# AT90CAN64 device description
Architecture: AVR8; Family: megaAVR
Registers are 8-bit, access not given, no defined reset value unless marked. A register's access mark holds for its fields unless they carry their own. Offsets are from the block's base; [hi:lo] are bit positions; 'fields as' and 'values as' point back to an identical list.

## USART1 — USART
Instances: USART1 0x00
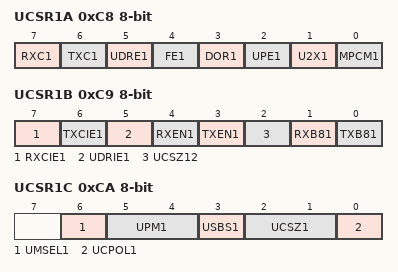
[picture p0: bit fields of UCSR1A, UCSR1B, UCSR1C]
0xC8 UCSR1A — USART Control and Status Register A
  [7] RXC1 — USART Receive Complete
  [6] TXC1 — USART Transmitt Complete
  [5] UDRE1 — USART Data Register Empty
  [4] FE1 — Framing Error
  [3] DOR1 — Data overRun
  [2] UPE1 — Parity Error
  [1] U2X1 — Double the USART transmission speed
  [0] MPCM1 — Multi-processor Communication Mode
0xC9 UCSR1B — USART Control and Status Register B
  [7] RXCIE1 — RX Complete Interrupt Enable
  [6] TXCIE1 — TX Complete Interrupt Enable
  [5] UDRIE1 — USART Data register Empty Interrupt Enable
  [4] RXEN1 — Receiver Enable
  [3] TXEN1 — Transmitter Enable
  [2] UCSZ12 — Character Size
  [1] RXB81 — Receive Data Bit 8
  [0] TXB81 — Transmit Data Bit 8
0xCA UCSR1C — USART Control and Status Register C
  [6] UMSEL1 — USART Mode Select
    0=Asynchronous Operation; 1=Synchronous Operation
  [5:4] UPM1 — Parity Mode Bits
    0=Disabled; 2=Enabled, Even Parity; 3=Enabled, Odd Parity
  [3] USBS1 — Stop Bit Select
    0=1-bit; 1=2-bit
  [2:1] UCSZ1 — Character Size
  [0] UCPOL1 — Clock Polarity
0xCC UBRR1 16-bit bits used 11:0 — USART Baud Rate Register t Bytes
0xCE UDR1 — USART I/O Data Register

## CPU — CPU Registers
Instances: CPU 0x00
Parameters: CORE_VERSION=V2E
0x3E GPIOR0 — General Purpose IO Register 0
0x4A GPIOR1 — General Purpose IO Register 1
0x4B GPIOR2 — General Purpose IO Register 2
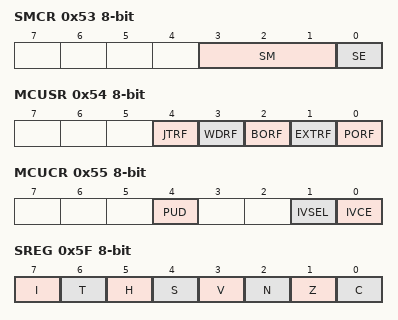
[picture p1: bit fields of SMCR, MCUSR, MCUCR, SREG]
0x53 SMCR — Sleep Mode Control Register
  [3:1] SM — Sleep Mode Select bits
    0=IDLE; 1=ADC (ADC Noise Reduction (If Available)); 2=PDOWN (Power Down); 3=PSAVE (Power Save); 6=STDBY (Standby)
  [0] SE — Sleep Enable
0x54 MCUSR — MCU Status Register
  [4] JTRF — JTAG Reset Flag
  [3] WDRF — Watchdog Reset Flag
  [2] BORF — Brown-out Reset Flag
  [1] EXTRF — External Reset Flag
  [0] PORF — Power-on reset flag
0x55 MCUCR — MCU Control Register
  [4] PUD — Pull-up disable
  [1] IVSEL — Interrupt Vector Select
  [0] IVCE — Interrupt Vector Change Enable
0x5B RAMPZ — RAM Page Z Select Register - Not used.
  [0] RAMPZ0 — RAM Page Z Select Register Bit 0
0x5D SP 16-bit — Stack Pointer
0x5F SREG — Status Register
  [7] I — Global Interrupt Enable
  [6] T — Bit Copy Storage
  [5] H — Half Carry Flag
  [4] S — Sign Bit
  [3] V — Two's Complement Overflow Flag
  [2] N — Negative Flag
  [1] Z — Zero Flag
  [0] C — Carry Flag
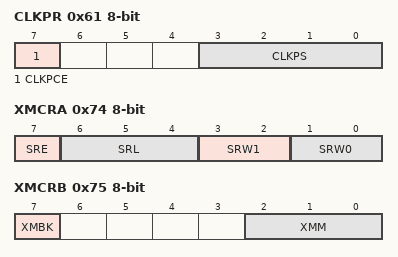
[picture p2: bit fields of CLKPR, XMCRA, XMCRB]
0x61 CLKPR — Clock Prescale Register
  [7] CLKPCE
  [3:0] CLKPS
    0=1; 1=2; 2=4; 3=8; 4=16; 5=32; 6=64; 7=128; 8=256
0x66 OSCCAL — Oscillator Calibration Value
  [7:0] OSCCAL — Oscillator Calibration
0x74 XMCRA — External Memory Control Register A
  [7] SRE — External SRAM Enable
  [6:4] SRL — Wait state page limit
    0=LS = N/A, US = 0x1100 - 0xFFFF; 1=LS = XMEMSTART - 0x1FFF, US = 0x2000 - 0xFFFF; 2=LS = XMEMSTART - 0x3FFF, US = 0x4000 - 0xFFFF; 3=LS = XMEMSTART - 0x5FFF, US = 0x6000 - 0xFFFF; 4=LS = XMEMSTART - 0x7FFF, US = 0x8000 - 0xFFFF; 5=LS = XMEMSTART - 0x9FFF, US = 0xA000 - 0xFFFF; 6=LS = XMEMSTART - 0xBFFF, US = 0xC000 - 0xFFFF; 7=LS = XMEMSTART - 0xDFFF, US = 0xE000 - 0xFFFF
  [3:2] SRW1 — Wait state select bit upper page
    0=No wait-states; 1=Wait one cycle during read/write strobe; 2=Wait two cycles during read/write strobe; 3=Wait two cycles during read/write and wait one cycle before driving out new address
  [1:0] SRW0 — Wait state select bit lower page
    values as SRW1
0x75 XMCRB — External Memory Control Register B
  [7] XMBK — External Memory Bus Keeper Enable
  [2:0] XMM — External Memory High Mask
Value list OSCCAL_VALUE_ADDRESSES: 0=8_0_MHz

## BOOT_LOAD — Bootloader
Instances: BOOT_LOAD 0x00
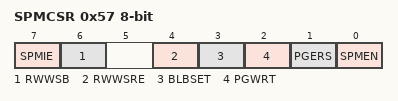
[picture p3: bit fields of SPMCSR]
0x57 SPMCSR — Store Program Memory Control Register
  [7] SPMIE — SPM Interrupt Enable
  [6] RWWSB — Read While Write Section Busy
  [4] RWWSRE — Read While Write section read enable
  [3] BLBSET — Boot Lock Bit Set
  [2] PGWRT — Page Write
  [1] PGERS — Page Erase
  [0] SPMEN — Store Program Memory Enable
